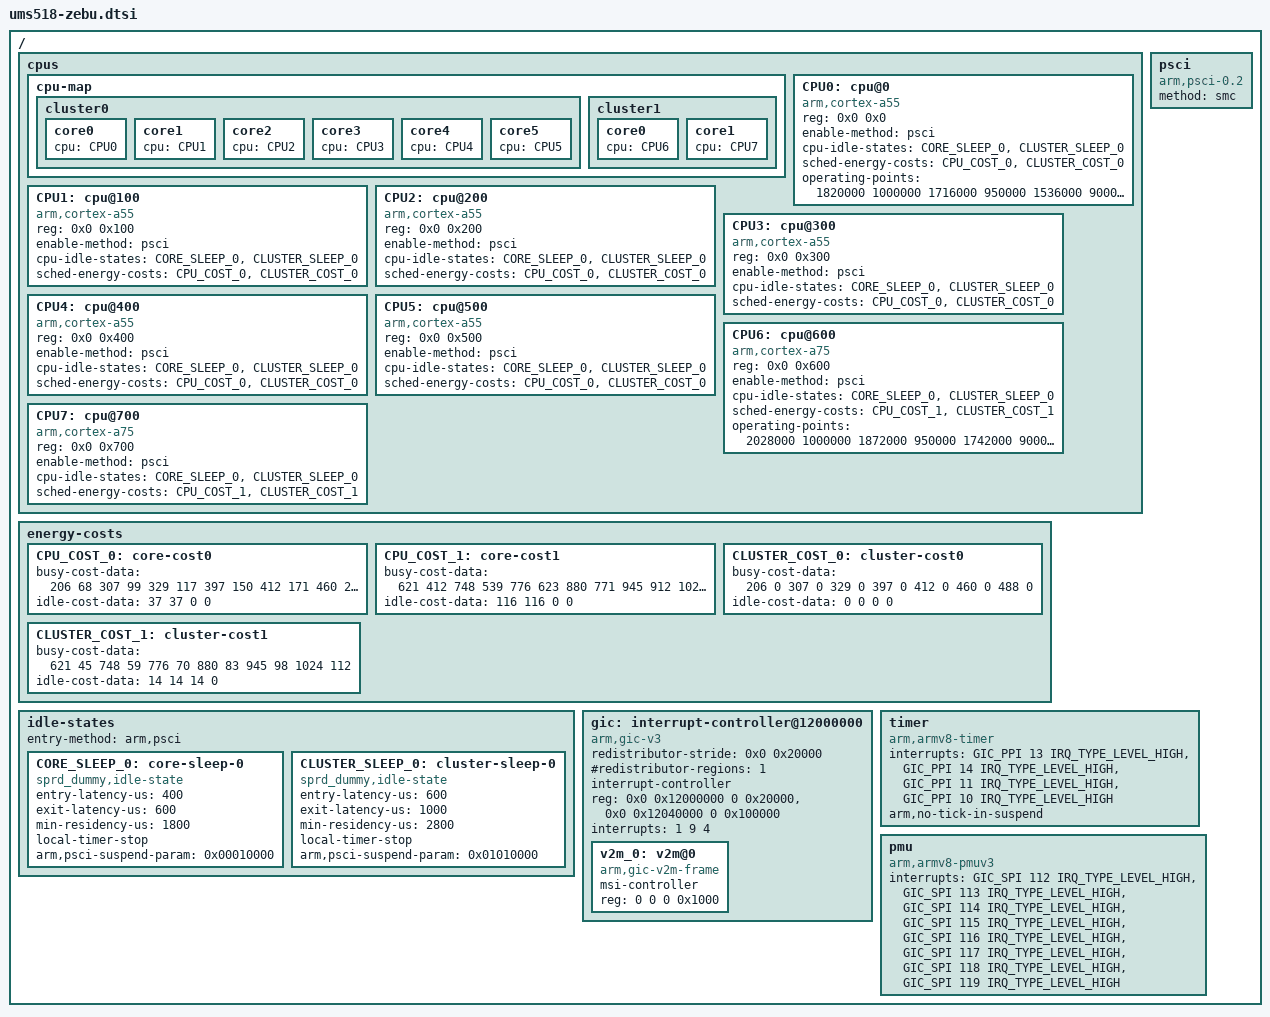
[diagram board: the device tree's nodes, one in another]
// SPDX-License-Identifier: (GPL-2.0+ OR MIT)
/*
 * Unisoc Sharkl5Pro platform DTS file
 *
 * Copyright (C) 2018, Unisoc Communications Inc.
 */

#include <dt-bindings/interrupt-controller/arm-gic.h>
#include "sharkl5pro-zebu.dtsi"

/ {
	cpus {
		#address-cells = <2>;
		#size-cells = <0>;

		cpu-map {
			cluster0 {
				core0 {
					cpu = <&CPU0>;
				};
				core1 {
					cpu = <&CPU1>;
				};
				core2 {
					cpu = <&CPU2>;
				};
				core3 {
					cpu = <&CPU3>;
				};
				core4 {
					cpu = <&CPU4>;
				};
				core5 {
					cpu = <&CPU5>;
				};
			};
			cluster1 {
				core0 {
					cpu = <&CPU6>;
				};
				core1 {
					cpu = <&CPU7>;
				};
			};
		};

		CPU0: cpu@0 {
			device_type = "cpu";
			compatible = "arm,cortex-a55","arm,armv8";
			reg = <0x0 0x0>;
			enable-method = "psci";
			cpu-idle-states = <&CORE_SLEEP_0 &CLUSTER_SLEEP_0>;
			sched-energy-costs = <&CPU_COST_0 &CLUSTER_COST_0>;
			operating-points = <
				1820000	1000000
				1716000 950000
				1536000 900000
				1482000 850000
				1228000 800000
				1144000 750000
				768000  700000
			>;
		};
		CPU1: cpu@100 {
			device_type = "cpu";
			compatible = "arm,cortex-a55","arm,armv8";
			reg = <0x0 0x100>;
			enable-method = "psci";
			cpu-idle-states = <&CORE_SLEEP_0 &CLUSTER_SLEEP_0>;
			sched-energy-costs = <&CPU_COST_0 &CLUSTER_COST_0>;
		};
		CPU2: cpu@200 {
			device_type = "cpu";
			compatible = "arm,cortex-a55","arm,armv8";
			reg = <0x0 0x200>;
			enable-method = "psci";
			cpu-idle-states = <&CORE_SLEEP_0 &CLUSTER_SLEEP_0>;
			sched-energy-costs = <&CPU_COST_0 &CLUSTER_COST_0>;
		};
		CPU3: cpu@300 {
			device_type = "cpu";
			compatible = "arm,cortex-a55","arm,armv8";
			reg = <0x0 0x300>;
			enable-method = "psci";
			cpu-idle-states = <&CORE_SLEEP_0 &CLUSTER_SLEEP_0>;
			sched-energy-costs = <&CPU_COST_0 &CLUSTER_COST_0>;
		};
		CPU4: cpu@400 {
			device_type = "cpu";
			compatible = "arm,cortex-a55","arm,armv8";
			reg = <0x0 0x400>;
			enable-method = "psci";
			cpu-idle-states = <&CORE_SLEEP_0 &CLUSTER_SLEEP_0>;
			sched-energy-costs = <&CPU_COST_0 &CLUSTER_COST_0>;
		};
		CPU5: cpu@500 {
			device_type = "cpu";
			compatible = "arm,cortex-a55","arm,armv8";
			reg = <0x0 0x500>;
			enable-method = "psci";
			cpu-idle-states = <&CORE_SLEEP_0 &CLUSTER_SLEEP_0>;
			sched-energy-costs = <&CPU_COST_0 &CLUSTER_COST_0>;
		};
		CPU6: cpu@600 {
			device_type = "cpu";
			compatible = "arm,cortex-a75","arm,armv8";
			reg = <0x0 0x600>;
			enable-method = "psci";
			cpu-idle-states = <&CORE_SLEEP_0 &CLUSTER_SLEEP_0>;
			sched-energy-costs = <&CPU_COST_1 &CLUSTER_COST_1>;
			operating-points = <
				2028000	1000000
				1872000 950000
				1742000 900000
				1536000 850000
				1482000 800000
				1229000 750000
			>;
		};
		CPU7: cpu@700 {
			device_type = "cpu";
			compatible = "arm,cortex-a75","arm,armv8";
			reg = <0x0 0x700>;
			enable-method = "psci";
			cpu-idle-states = <&CORE_SLEEP_0 &CLUSTER_SLEEP_0>;
			sched-energy-costs = <&CPU_COST_1 &CLUSTER_COST_1>;
		};
	};

	energy-costs {
		CPU_COST_0: core-cost0 {
			busy-cost-data = <
				206 68
				307 99
				329 117
				397 150
				412 171
				460 207
				488 241
			>;
			idle-cost-data = <
				37		/* ACTIVE-IDLE */
				37
				0
				0
			>;
		};
		CPU_COST_1: core-cost1 {
			busy-cost-data = <
				621 412
				748 539
				776 623
				880 771
				945 912
				1024 1083
			>;
			idle-cost-data = <
				116		// ACTIVE-IDLE
				116
				0
				0
			>;
		};
		CLUSTER_COST_0: cluster-cost0 {
			busy-cost-data = <
				206 0
				307 0
				329 0
				397 0
				412 0
				460 0
				488 0
			>;
			idle-cost-data = <
				0		// ACTIVE-IDLE
				0
				0
				0
			>;
		};
		CLUSTER_COST_1: cluster-cost1 {
			busy-cost-data = <
				621 45
				748 59
				776 70
				880 83
				945 98
				1024 112
			>;
			idle-cost-data = <
				14		// ACTIVE-IDLE
				14
				14
				0
			>;
		};
	};

	psci {
		compatible = "arm,psci-0.2";
		method = "smc";
	};

	idle-states {
		entry-method = "arm,psci";
		CORE_SLEEP_0: core-sleep-0 {
			compatible = "sprd_dummy,idle-state";
			entry-latency-us = <400>;
			exit-latency-us = <600>;
			min-residency-us = <1800>;
			local-timer-stop;
			arm,psci-suspend-param = <0x00010000>;
		};
		CLUSTER_SLEEP_0: cluster-sleep-0 {
			compatible = "sprd_dummy,idle-state";
			entry-latency-us = <600>;
			exit-latency-us = <1000>;
			min-residency-us = <2800>;
			local-timer-stop;
			arm,psci-suspend-param = <0x01010000>;
		};
	};

	gic: interrupt-controller@12000000 {
		compatible = "arm,gic-v3";
		#interrupt-cells = <3>;
		#address-cells = <2>;
		#size-cells = <2>;
		ranges;
		redistributor-stride = <0x0 0x20000>;	/* 128KB stride */
		#redistributor-regions = <1>;
		interrupt-controller;
		reg = <0x0 0x12000000 0 0x20000>,	/* GICD */
			<0x0 0x12040000 0 0x100000>;	/* GICR */
		interrupts = <1 9 4>;
		v2m_0: v2m@0 {
			compatible = "arm,gic-v2m-frame";
			msi-controller;
			reg = <0 0 0 0x1000>;
		};
	};

	timer {
		compatible = "arm,armv8-timer";
		interrupts = <GIC_PPI 13 IRQ_TYPE_LEVEL_HIGH>, /* Physical Secure PPI */
			<GIC_PPI 14 IRQ_TYPE_LEVEL_HIGH>, /* Physical Non-Secure PPI */
			<GIC_PPI 11 IRQ_TYPE_LEVEL_HIGH>, /* Virtual PPI */
			<GIC_PPI 10 IRQ_TYPE_LEVEL_HIGH>; /* Hipervisor PPI */
		arm,no-tick-in-suspend;
	};

	pmu {
		compatible = "arm,armv8-pmuv3";
		interrupts = <GIC_SPI 112 IRQ_TYPE_LEVEL_HIGH>,
			<GIC_SPI 113 IRQ_TYPE_LEVEL_HIGH>,
			<GIC_SPI 114 IRQ_TYPE_LEVEL_HIGH>,
			<GIC_SPI 115 IRQ_TYPE_LEVEL_HIGH>,
			<GIC_SPI 116 IRQ_TYPE_LEVEL_HIGH>,
			<GIC_SPI 117 IRQ_TYPE_LEVEL_HIGH>,
			<GIC_SPI 118 IRQ_TYPE_LEVEL_HIGH>,
			<GIC_SPI 119 IRQ_TYPE_LEVEL_HIGH>;
	};
};
